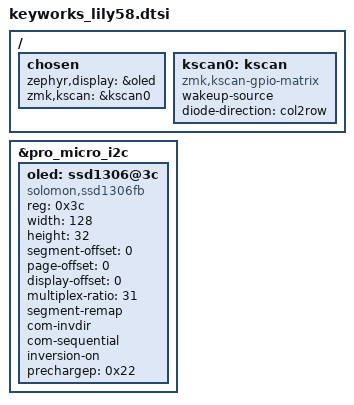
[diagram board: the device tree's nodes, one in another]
/*
 * Copyright (c) 2022 The ZMK Contributors
 *
 * SPDX-License-Identifier: MIT
 */

#include "keyworks_lily58_layout.dtsi"
#include "keyworks_lily58_sensors.dtsi"

/ {
    chosen {
        zephyr,display = &oled;
        zmk,kscan = &kscan0;
    };

    kscan0: kscan {
        compatible = "zmk,kscan-gpio-matrix";
        wakeup-source;
        diode-direction = "col2row";
    };

};

&pro_micro_i2c {
    status = "okay";

    oled: ssd1306@3c {
        compatible = "solomon,ssd1306fb";
        reg = <0x3c>;
        width = <128>;
        height = <32>;
        segment-offset = <0>;
        page-offset = <0>;
        display-offset = <0>;
        multiplex-ratio = <31>;
        segment-remap;
        com-invdir;
        com-sequential;
        inversion-on;
        prechargep = <0x22>;
    };
};
